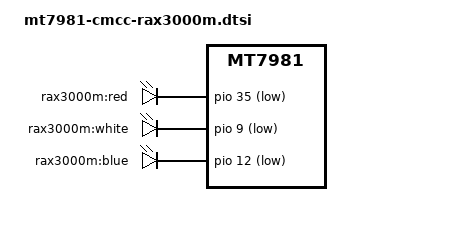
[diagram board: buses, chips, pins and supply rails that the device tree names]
/dts-v1/;
#include "mt7981.dtsi"

/ {
	aliases {
		led-boot = &red_led;
		led-failsafe = &red_led;
		led-running = &white_led;
		led-upgrade = &blue_led;
	};

	leds {
		compatible = "gpio-leds";

		red_led: red {
			label = "rax3000m:red";
			gpios = <&pio 35 GPIO_ACTIVE_LOW>;
		};

		white_led: white {
			label = "rax3000m:white";
			gpios = <&pio 9 GPIO_ACTIVE_LOW>;
		};

		blue_led: blue {
			label = "rax3000m:blue";
			gpios = <&pio 12 GPIO_ACTIVE_LOW>;
		};
	};
};
